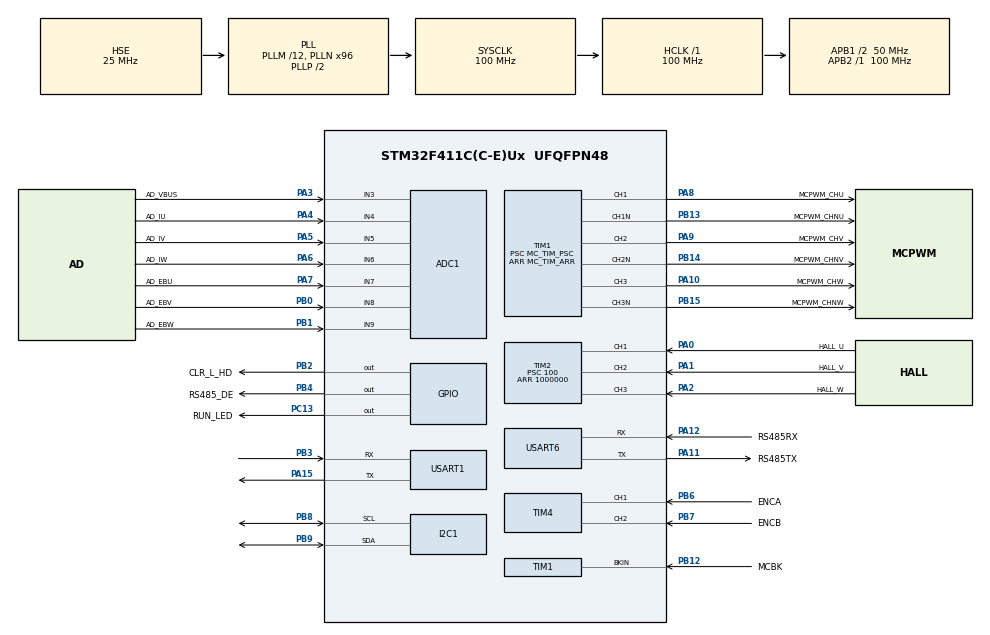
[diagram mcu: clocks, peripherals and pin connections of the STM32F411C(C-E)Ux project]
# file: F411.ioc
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ADC1.Channel-1\#ChannelRegularConversion=ADC_CHANNEL_3
ADC1.Channel-2\#ChannelInjectedConversion=ADC_CHANNEL_4
ADC1.Channel-3\#ChannelInjectedConversion=ADC_CHANNEL_5
ADC1.Channel-4\#ChannelInjectedConversion=ADC_CHANNEL_6
ADC1.ContinuousConvMode=DISABLE
ADC1.EnableAnalogWatchDog=false
ADC1.ExternalTrigInjecConv=ADC_EXTERNALTRIGINJECCONV_T1_CC4
ADC1.ExternalTrigInjecConvEdge=ADC_EXTERNALTRIGINJECCONVEDGE_RISING
ADC1.InjNumberOfConversion=3
ADC1.InjectedConvMode=None
ADC1.InjectedOffset-2\#ChannelInjectedConversion=0
ADC1.InjectedOffset-3\#ChannelInjectedConversion=0
ADC1.InjectedOffset-4\#ChannelInjectedConversion=0
ADC1.InjectedRank-2\#ChannelInjectedConversion=1
ADC1.InjectedRank-3\#ChannelInjectedConversion=2
ADC1.InjectedRank-4\#ChannelInjectedConversion=3
ADC1.NbrOfConversion=1
ADC1.NbrOfConversionFlag=1
ADC1.Rank-1\#ChannelRegularConversion=1
ADC1.SamplingTime-1\#ChannelRegularConversion=ADC_SAMPLETIME_3CYCLES
ADC1.SamplingTime-2\#ChannelInjectedConversion=ADC_SAMPLETIME_3CYCLES
ADC1.SamplingTime-3\#ChannelInjectedConversion=ADC_SAMPLETIME_3CYCLES
ADC1.SamplingTime-4\#ChannelInjectedConversion=ADC_SAMPLETIME_3CYCLES
ADC1.master=1
Dma.ADC1.0.Direction=DMA_PERIPH_TO_MEMORY
Dma.ADC1.0.FIFOMode=DMA_FIFOMODE_DISABLE
Dma.ADC1.0.Instance=DMA2_Stream4
Dma.ADC1.0.MemDataAlignment=DMA_MDATAALIGN_HALFWORD
Dma.ADC1.0.MemInc=DMA_MINC_ENABLE
Dma.ADC1.0.Mode=DMA_NORMAL
Dma.ADC1.0.PeriphDataAlignment=DMA_PDATAALIGN_HALFWORD
Dma.ADC1.0.PeriphInc=DMA_PINC_DISABLE
Dma.ADC1.0.Priority=DMA_PRIORITY_LOW
Dma.Request0=ADC1
Dma.Request1=USART6_RX
Dma.Request2=USART6_TX
Dma.Request3=USART1_RX
Dma.USART1_RX.3.Direction=DMA_PERIPH_TO_MEMORY
Dma.USART1_RX.3.FIFOMode=DMA_FIFOMODE_DISABLE
Dma.USART1_RX.3.Instance=DMA2_Stream2
Dma.USART1_RX.3.MemDataAlignment=DMA_MDATAALIGN_BYTE
Dma.USART1_RX.3.MemInc=DMA_MINC_ENABLE
Dma.USART1_RX.3.Mode=DMA_NORMAL
Dma.USART1_RX.3.PeriphDataAlignment=DMA_PDATAALIGN_BYTE
Dma.USART1_RX.3.PeriphInc=DMA_PINC_DISABLE
Dma.USART1_RX.3.Priority=DMA_PRIORITY_LOW
Dma.USART6_RX.1.Direction=DMA_PERIPH_TO_MEMORY
Dma.USART6_RX.1.FIFOMode=DMA_FIFOMODE_DISABLE
Dma.USART6_RX.1.Instance=DMA2_Stream1
Dma.USART6_RX.1.MemDataAlignment=DMA_MDATAALIGN_BYTE
Dma.USART6_RX.1.MemInc=DMA_MINC_ENABLE
Dma.USART6_RX.1.Mode=DMA_NORMAL
Dma.USART6_RX.1.PeriphDataAlignment=DMA_PDATAALIGN_BYTE
Dma.USART6_RX.1.PeriphInc=DMA_PINC_DISABLE
Dma.USART6_RX.1.Priority=DMA_PRIORITY_LOW
Dma.USART6_TX.2.Direction=DMA_MEMORY_TO_PERIPH
Dma.USART6_TX.2.FIFOMode=DMA_FIFOMODE_DISABLE
Dma.USART6_TX.2.Instance=DMA2_Stream6
Dma.USART6_TX.2.MemDataAlignment=DMA_MDATAALIGN_BYTE
Dma.USART6_TX.2.MemInc=DMA_MINC_ENABLE
Dma.USART6_TX.2.Mode=DMA_NORMAL
Dma.USART6_TX.2.PeriphDataAlignment=DMA_PDATAALIGN_BYTE
Dma.USART6_TX.2.PeriphInc=DMA_PINC_DISABLE
Dma.USART6_TX.2.Priority=DMA_PRIORITY_LOW
Mcu.Family=STM32F4
Mcu.Name=STM32F411C(C-E)Ux
Mcu.Package=UFQFPN48
Mcu.UserConstants=MC_TIM_PSC,(0);MC_TIM_ARR,(5000)
NVIC.ADC_IRQn=true\:0\:0\:false\:false\:true\:false\:true\:true\:true
NVIC.DMA2_Stream1_IRQn=true\:0\:0\:false\:false\:true\:false\:false\:true\:true
NVIC.DMA2_Stream2_IRQn=true\:0\:0\:false\:false\:true\:true\:false\:true\:true
NVIC.DMA2_Stream4_IRQn=true\:0\:0\:false\:false\:true\:false\:false\:true\:true
NVIC.DMA2_Stream6_IRQn=true\:0\:0\:false\:false\:true\:false\:false\:true\:true
NVIC.PriorityGroup=NVIC_PRIORITYGROUP_4
NVIC.TIM1_BRK_TIM9_IRQn=true\:15\:0\:false\:false\:true\:false\:false\:true\:true
NVIC.TIM1_UP_TIM10_IRQn=true\:15\:0\:false\:false\:true\:false\:false\:true\:true
NVIC.TIM2_IRQn=true\:0\:0\:false\:false\:true\:false\:true\:true\:true
NVIC.TimeBase=TIM1_BRK_TIM9_IRQn
NVIC.TimeBaseIP=TIM9
NVIC.USART1_IRQn=true\:15\:0\:true\:false\:true\:false\:true\:true\:true
NVIC.USART6_IRQn=true\:0\:0\:false\:false\:true\:false\:true\:true\:true
PA0-WKUP.GPIO_Label=HALL_U
PA0-WKUP.GPIO_Speed=GPIO_SPEED_FREQ_MEDIUM
PA0-WKUP.Signal=S_TIM2_CH1_ETR
PA1.GPIO_Label=HALL_V
PA1.GPIO_PuPd=GPIO_NOPULL
PA1.GPIO_Speed=GPIO_SPEED_FREQ_MEDIUM
PA1.Signal=S_TIM2_CH2
PA10.GPIO_Label=MCPWM_CHW
PA10.GPIO_Speed=GPIO_SPEED_FREQ_VERY_HIGH
PA10.Signal=S_TIM1_CH3
PA11.GPIO_Label=RS485TX
PA11.Mode=Asynchronous
PA11.Signal=USART6_TX
PA12.GPIO_Label=RS485RX
PA12.Mode=Asynchronous
PA12.Signal=USART6_RX
PA13.Mode=Serial_Wire
PA13.Signal=SYS_JTMS-SWDIO
PA14.Mode=Serial_Wire
PA14.Signal=SYS_JTCK-SWCLK
PA15.Mode=Asynchronous
PA15.Signal=USART1_TX
PA2.GPIO_Label=HALL_W
PA2.GPIO_Speed=GPIO_SPEED_FREQ_MEDIUM
PA2.Signal=S_TIM2_CH3
PA3.GPIO_Label=AD_VBUS
PA3.Signal=ADCx_IN3
PA4.GPIO_Label=AD_IU
PA4.Signal=ADCx_IN4
PA5.GPIO_Label=AD_IV
PA5.Signal=ADCx_IN5
PA6.GPIO_Label=AD_IW
PA6.Signal=ADCx_IN6
PA7.GPIO_Label=AD_EBU
PA7.Signal=ADCx_IN7
PA8.GPIO_Label=MCPWM_CHU
PA8.GPIO_Speed=GPIO_SPEED_FREQ_VERY_HIGH
PA8.Signal=S_TIM1_CH1
PA9.GPIO_Label=MCPWM_CHV
PA9.GPIO_Speed=GPIO_SPEED_FREQ_VERY_HIGH
PA9.Signal=S_TIM1_CH2
PB0.GPIO_Label=AD_EBV
PB0.Signal=ADCx_IN8
PB1.GPIO_Label=AD_EBW
PB1.Signal=ADCx_IN9
PB12.GPIO_Label=MCBK
PB12.Mode=Activate-Break-Input
PB12.Signal=TIM1_BKIN
PB13.GPIO_Label=MCPWM_CHNU
PB13.GPIO_Speed=GPIO_SPEED_FREQ_VERY_HIGH
PB13.Mode=PWM Generation1 CH1 CH1N
PB13.Signal=TIM1_CH1N
PB14.GPIO_Label=MCPWM_CHNV
PB14.GPIO_Speed=GPIO_SPEED_FREQ_VERY_HIGH
PB14.Mode=PWM Generation2 CH2 CH2N
PB14.Signal=TIM1_CH2N
PB15.GPIO_Label=MCPWM_CHNW
PB15.GPIO_Speed=GPIO_SPEED_FREQ_VERY_HIGH
PB15.Mode=PWM Generation3 CH3 CH3N
PB15.Signal=TIM1_CH3N
PB2.GPIO_Label=CLR_L_HD
PB2.Signal=GPIO_Output
PB3.Mode=Asynchronous
PB3.Signal=USART1_RX
PB4.GPIO_Label=RS485_DE
PB4.Signal=GPIO_Output
PB6.GPIO_Label=ENCA
PB6.Signal=S_TIM4_CH1
PB7.GPIO_Label=ENCB
PB7.Signal=S_TIM4_CH2
PB8.Mode=I2C
PB8.Signal=I2C1_SCL
PB9.Mode=I2C
PB9.Signal=I2C1_SDA
PC13-ANTI_TAMP.GPIO_Label=RUN_LED
PC13-ANTI_TAMP.Signal=GPIO_Output
PH0\ -\ OSC_IN.Mode=HSE-External-Oscillator
PH0\ -\ OSC_IN.Signal=RCC_OSC_IN
PH1\ -\ OSC_OUT.Mode=HSE-External-Oscillator
PH1\ -\ OSC_OUT.Signal=RCC_OSC_OUT
ProjectManager.HeapSize=0x200
ProjectManager.StackSize=0x400
ProjectManager.TargetToolchain=MDK-ARM V5.32
RCC.48MHZClocksFreq_Value=50000000
RCC.AHBFreq_Value=100000000
RCC.APB1CLKDivider=RCC_HCLK_DIV2
RCC.APB1Freq_Value=50000000
RCC.APB1TimFreq_Value=100000000
RCC.APB2Freq_Value=100000000
RCC.APB2TimFreq_Value=100000000
RCC.CortexFreq_Value=100000000
RCC.HCLKFreq_Value=100000000
RCC.HSE_VALUE=25000000
RCC.HSI_VALUE=16000000
RCC.LSE_VALUE=32768
RCC.PLLM=12
RCC.PLLN=96
RCC.PLLSourceVirtual=RCC_PLLSOURCE_HSE
RCC.SYSCLKFreq_VALUE=100000000
RCC.SYSCLKSource=RCC_SYSCLKSOURCE_PLLCLK
RCC.VCOOutputFreq_Value=200000000
RealThread.X-CUBE-RT-Thread_Nano.4.1.1.RTAaThreadCcRTOSJjkernel=true
RealThread.X-CUBE-RT-Thread_Nano.4.1.1.RTAaThreadCcRTOSJjlibcpu=true
RealThread.X-CUBE-RT-Thread_Nano.4.1.1.RTAaThreadCcRTOSJjshell=true
RealThread.X-CUBE-RT-Thread_Nano.4.1.1.RT_USING_EVENT=1
RealThread.X-CUBE-RT-Thread_Nano.4.1.1.RT_USING_FINSH=1
RealThread.X-CUBE-RT-Thread_Nano.4.1.1.RT_USING_HEAP=1
RealThread.X-CUBE-RT-Thread_Nano.4.1.1.RT_USING_MAILBOX=1
RealThread.X-CUBE-RT-Thread_Nano.4.1.1.RT_USING_MESSAGEQUEUE=1
RealThread.X-CUBE-RT-Thread_Nano.4.1.1.RT_USING_MUTEX=1
RealThread.X-CUBE-RT-Thread_Nano.4.1.1.RT_USING_SIGNALS=0
RealThread.X-CUBE-RT-Thread_Nano.4.1.1.RT_USING_SMALL_MEM=1
RealThread.X-CUBE-RT-Thread_Nano.4.1.1.RT_USING_SMALL_MEM_AS_HEAP=1
SH.ADCx_IN3.0=ADC1_IN3,IN3
SH.ADCx_IN4.0=ADC1_IN4,IN4
SH.ADCx_IN5.0=ADC1_IN5,IN5
SH.ADCx_IN6.0=ADC1_IN6,IN6
SH.ADCx_IN7.0=ADC1_IN7,IN7
SH.ADCx_IN8.0=ADC1_IN8,IN8
SH.ADCx_IN9.0=ADC1_IN9,IN9
SH.S_TIM1_CH1.0=TIM1_CH1,PWM Generation1 CH1 CH1N
SH.S_TIM1_CH2.0=TIM1_CH2,PWM Generation2 CH2 CH2N
SH.S_TIM1_CH3.0=TIM1_CH3,PWM Generation3 CH3 CH3N
SH.S_TIM2_CH1_ETR.0=TIM2_CH1,Xored_Inputs_Hall_Sensor_Interface
SH.S_TIM2_CH2.0=TIM2_CH2,Xored_Inputs_Hall_Sensor_Interface
SH.S_TIM2_CH3.0=TIM2_CH3,Xored_Inputs_Hall_Sensor_Interface
SH.S_TIM4_CH1.0=TIM4_CH1,Encoder_Interface
SH.S_TIM4_CH2.0=TIM4_CH2,Encoder_Interface
STMicroelectronics.X-CUBE-ALGOBUILD.1.4.0.LibraryCcDSPOoLibraryJjDSPOoLibrary=true
TIM1.AutoReloadPreload=TIM_AUTORELOAD_PRELOAD_ENABLE
TIM1.BreakState=TIM_BREAK_DISABLE
TIM1.Channel-PWM\ Generation1\ CH1\ CH1N=TIM_CHANNEL_1
TIM1.Channel-PWM\ Generation2\ CH2\ CH2N=TIM_CHANNEL_2
TIM1.Channel-PWM\ Generation3\ CH3\ CH3N=TIM_CHANNEL_3
TIM1.Channel-PWM\ Generation4\ No\ Output=TIM_CHANNEL_4
TIM1.CounterMode=TIM_COUNTERMODE_CENTERALIGNED1
TIM1.DeadTime=50
TIM1.OCMode_PWM-PWM\ Generation4\ No\ Output=TIM_OCMODE_PWM2
TIM1.Period=MC_TIM_ARR
TIM1.Prescaler=MC_TIM_PSC
TIM1.Pulse-PWM\ Generation4\ No\ Output=MC_TIM_ARR-5
TIM1.TIM_MasterOutputTrigger=TIM_TRGO_OC4REF
TIM2.IC1Filter=2
TIM2.Period=1000000
TIM2.Prescaler=100
USART1.VirtualMode=VM_ASYNC
USART6.Parity=PARITY_EVEN
USART6.VirtualMode=VM_ASYNC
VP_RealThread.X-CUBE-RT-Thread_Nano_VS_RTOSJjRTAaThread_4.1.1_4.1.1.Mode=RTOSJjRTAaThread
VP_STMicroelectronics.X-CUBE-ALGOBUILD_VS_DSPOoLibraryJjLibrary_1.4.0_1.4.0.Mode=DSPOoLibraryJjLibrary
VP_SYS_VS_tim9.Mode=TIM9
VP_TIM1_VS_ClockSourceINT.Mode=Internal
VP_TIM1_VS_no_output4.Mode=PWM Generation4 No Output
board=custom

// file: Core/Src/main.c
/* USER CODE BEGIN Header */
/**
  ******************************************************************************
  * @file           : main.c
  * @brief          : Main program body
  ******************************************************************************
  * @attention
  *
  * Copyright (c) 2025 STMicroelectronics.
  * All rights reserved.
  *
  * This software is licensed under terms that can be found in the LICENSE file
  * in the root directory of this software component.
  * If no LICENSE file comes with this software, it is provided AS-IS.
  *
  ******************************************************************************
  */
/* USER CODE END Header */
#include "main.h"
#include "adc.h"
#include "dma.h"
#include "i2c.h"
#include "tim.h"
#include "usart.h"
#include "gpio.h"

/* USER CODE BEGIN Includes */
#include "arm_math.h"
#include "rtthread.h"
#include "drv_mc.h"
#include "drv_hall.h"

/* USER CODE END Includes */

void SystemClock_Config(void);

int main(void)
{

  /* MCU Configuration--------------------------------------------------------*/

  /* Reset of all peripherals, Initializes the Flash interface and the Systick. */
  HAL_Init();

  /* Configure the system clock */
  SystemClock_Config();

  /* USER CODE BEGIN SysInit */
    goto JUMP_CUBE_INIT;        //NOTE: 使用rtthread初始化
  /* USER CODE END SysInit */

  /* Initialize all configured peripherals */
  MX_GPIO_Init();
  MX_DMA_Init();
  MX_ADC1_Init();
  MX_I2C1_Init();
  MX_TIM1_Init();
  MX_TIM2_Init();
  MX_TIM4_Init();
  MX_USART1_UART_Init();
  MX_USART6_UART_Init();
  /* USER CODE BEGIN 2 */
  JUMP_CUBE_INIT:
  //DrvMc_Init();
  hall_sor1.installation_angle = DRV_HALL_INSTALLATION_ANGLE120;
  DrvHall_Init(&hall_sor1);
  /* USER CODE END 2 */

  /* Infinite loop */
  /* USER CODE BEGIN WHILE */
  while (1)
  {
     HAL_GPIO_TogglePin(RUN_LED_GPIO_Port,RUN_LED_Pin);
     rt_thread_mdelay(500);
    /* USER CODE END WHILE */

  }
}

void SystemClock_Config(void)
{
  RCC_OscInitTypeDef RCC_OscInitStruct = {0};
  RCC_ClkInitTypeDef RCC_ClkInitStruct = {0};

  /** Configure the main internal regulator output voltage
  */
  __HAL_RCC_PWR_CLK_ENABLE();
  __HAL_PWR_VOLTAGESCALING_CONFIG(PWR_REGULATOR_VOLTAGE_SCALE1);

  /** Initializes the RCC Oscillators according to the specified parameters
  * in the RCC_OscInitTypeDef structure.
  */
  RCC_OscInitStruct.OscillatorType = RCC_OSCILLATORTYPE_HSE;
  RCC_OscInitStruct.HSEState = RCC_HSE_ON;
  RCC_OscInitStruct.PLL.PLLState = RCC_PLL_ON;
  RCC_OscInitStruct.PLL.PLLSource = RCC_PLLSOURCE_HSE;
  RCC_OscInitStruct.PLL.PLLM = 12;
  RCC_OscInitStruct.PLL.PLLN = 96;
  RCC_OscInitStruct.PLL.PLLP = RCC_PLLP_DIV2;
  RCC_OscInitStruct.PLL.PLLQ = 4;
  if (HAL_RCC_OscConfig(&RCC_OscInitStruct) != HAL_OK)
  {
    Error_Handler();
  }

  /** Initializes the CPU, AHB and APB buses clocks
  */
  RCC_ClkInitStruct.ClockType = RCC_CLOCKTYPE_HCLK|RCC_CLOCKTYPE_SYSCLK
                              |RCC_CLOCKTYPE_PCLK1|RCC_CLOCKTYPE_PCLK2;
  RCC_ClkInitStruct.SYSCLKSource = RCC_SYSCLKSOURCE_PLLCLK;
  RCC_ClkInitStruct.AHBCLKDivider = RCC_SYSCLK_DIV1;
  RCC_ClkInitStruct.APB1CLKDivider = RCC_HCLK_DIV2;
  RCC_ClkInitStruct.APB2CLKDivider = RCC_HCLK_DIV1;

  if (HAL_RCC_ClockConfig(&RCC_ClkInitStruct, FLASH_LATENCY_3) != HAL_OK)
  {
    Error_Handler();
  }
}

void HAL_TIM_PeriodElapsedCallback(TIM_HandleTypeDef *htim)
{
  if (htim->Instance == TIM9) {
    HAL_IncTick();
  }
  /* USER CODE BEGIN Callback 1 */
  if(htim->Instance == TIM2){

  }

  /* USER CODE END Callback 1 */
}

void Error_Handler(void)
{
  __disable_irq();
  while (1)
  {
  }
}
